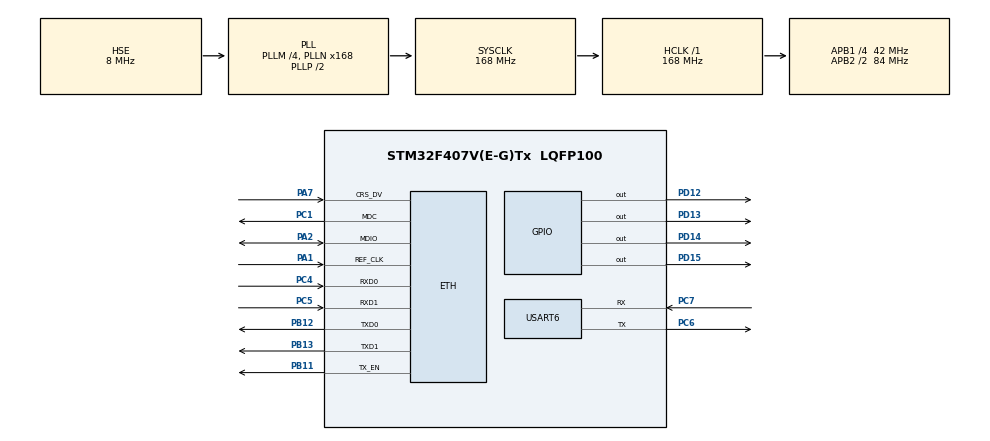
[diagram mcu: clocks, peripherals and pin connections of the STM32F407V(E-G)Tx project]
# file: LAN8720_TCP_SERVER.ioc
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ETH.MACAddr=00\:13\:37\:01\:23\:45
ETH.MediaInterface=ETH_MEDIA_INTERFACE_RMII
ETH.PhyAddress=0
LWIP.GATEWAY_ADDRESS=192.168.001.001
LWIP.IP_ADDRESS=192.168.001.193
LWIP.LWIP_DHCP=0
LWIP.MEMP_NUM_TCP_SEG=24
LWIP.NETMASK_ADDRESS=255.255.255.000
LWIP.TCP_MSS=460
LWIP.TCP_SND_BUF=1840
LWIP.TCP_WND=2048
LWIP.Version=v2.0.0_Cube
Mcu.Family=STM32F4
Mcu.Name=STM32F407V(E-G)Tx
Mcu.Package=LQFP100
NVIC.PriorityGroup=NVIC_PRIORITYGROUP_4
NVIC.TIM2_IRQn=true\:0\:0\:false\:false\:true\:true
NVIC.USART6_IRQn=true\:0\:0\:false\:false\:true\:true
PA1.Mode=RMII
PA1.Signal=ETH_REF_CLK
PA13.Mode=Serial_Wire
PA13.Signal=SYS_JTMS-SWDIO
PA14.Mode=Serial_Wire
PA14.Signal=SYS_JTCK-SWCLK
PA2.Mode=RMII
PA2.Signal=ETH_MDIO
PA7.Mode=RMII
PA7.Signal=ETH_CRS_DV
PB11.Mode=RMII
PB11.Signal=ETH_TX_EN
PB12.Mode=RMII
PB12.Signal=ETH_TXD0
PB13.Mode=RMII
PB13.Signal=ETH_TXD1
PC1.Mode=RMII
PC1.Signal=ETH_MDC
PC4.Mode=RMII
PC4.Signal=ETH_RXD0
PC5.Mode=RMII
PC5.Signal=ETH_RXD1
PC6.Mode=Asynchronous
PC6.Signal=USART6_TX
PC7.Mode=Asynchronous
PC7.Signal=USART6_RX
PD12.Signal=GPIO_Output
PD13.Signal=GPIO_Output
PD14.Signal=GPIO_Output
PD15.Signal=GPIO_Output
PH0-OSC_IN.Mode=HSE-External-Oscillator
PH0-OSC_IN.Signal=RCC_OSC_IN
PH1-OSC_OUT.Mode=HSE-External-Oscillator
PH1-OSC_OUT.Signal=RCC_OSC_OUT
ProjectManager.HeapSize=0x2000
ProjectManager.StackSize=0x4000
ProjectManager.TargetToolchain=SW4STM32
RCC.48MHZClocksFreq_Value=84000000
RCC.AHBFreq_Value=168000000
RCC.APB1CLKDivider=RCC_HCLK_DIV4
RCC.APB1Freq_Value=42000000
RCC.APB1TimFreq_Value=84000000
RCC.APB2CLKDivider=RCC_HCLK_DIV2
RCC.APB2Freq_Value=84000000
RCC.APB2TimFreq_Value=168000000
RCC.CortexFreq_Value=168000000
RCC.HCLKFreq_Value=168000000
RCC.HSE_VALUE=8000000
RCC.HSI_VALUE=16000000
RCC.LSE_VALUE=32768
RCC.PLLM=4
RCC.PLLN=168
RCC.PLLSourceVirtual=RCC_PLLSOURCE_HSE
RCC.SYSCLKFreq_VALUE=168000000
RCC.SYSCLKSource=RCC_SYSCLKSOURCE_PLLCLK
RCC.VCOOutputFreq_Value=336000000
TIM2.Period=1000
TIM2.Prescaler=41999
TIM2.TIM_MasterOutputTrigger=TIM_TRGO_UPDATE
USART6.VirtualMode=VM_ASYNC
VP_LWIP_VS_Enabled.Mode=Enabled
VP_TIM2_VS_ClockSourceINT.Mode=Internal
board=LAN8720_TCP_SERVER

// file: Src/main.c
/**
  ******************************************************************************
  * File Name          : main.c
  * Description        : Main program body
  ******************************************************************************
  * This notice applies to any and all portions of this file
  * that are not between comment pairs USER CODE BEGIN and
  * USER CODE END. Other portions of this file, whether
  * inserted by the user or by software development tools
  * are owned by their respective copyright owners.
  *
  * Copyright (c) 2017 STMicroelectronics International N.V.
  * All rights reserved.
  *
  * Redistribution and use in source and binary forms, with or without
  * modification, are permitted, provided that the following conditions are met:
  *
  * 1. Redistribution of source code must retain the above copyright notice,
  *    this list of conditions and the following disclaimer.
  * 2. Redistributions in binary form must reproduce the above copyright notice,
  *    this list of conditions and the following disclaimer in the documentation
  *    and/or other materials provided with the distribution.
  * 3. Neither the name of STMicroelectronics nor the names of other
  *    contributors to this software may be used to endorse or promote products
  *    derived from this software without specific written permission.
  * 4. This software, including modifications and/or derivative works of this
  *    software, must execute solely and exclusively on microcontroller or
  *    microprocessor devices manufactured by or for STMicroelectronics.
  * 5. Redistribution and use of this software other than as permitted under
  *    this license is void and will automatically terminate your rights under
  *    this license.
  *
  * THIS SOFTWARE IS PROVIDED BY STMICROELECTRONICS AND CONTRIBUTORS "AS IS"
  * AND ANY EXPRESS, IMPLIED OR STATUTORY WARRANTIES, INCLUDING, BUT NOT
  * LIMITED TO, THE IMPLIED WARRANTIES OF MERCHANTABILITY, FITNESS FOR A
  * PARTICULAR PURPOSE AND NON-INFRINGEMENT OF THIRD PARTY INTELLECTUAL PROPERTY
  * RIGHTS ARE DISCLAIMED TO THE FULLEST EXTENT PERMITTED BY LAW. IN NO EVENT
  * SHALL STMICROELECTRONICS OR CONTRIBUTORS BE LIABLE FOR ANY DIRECT, INDIRECT,
  * INCIDENTAL, SPECIAL, EXEMPLARY, OR CONSEQUENTIAL DAMAGES (INCLUDING, BUT NOT
  * LIMITED TO, PROCUREMENT OF SUBSTITUTE GOODS OR SERVICES; LOSS OF USE, DATA,
  * OR PROFITS; OR BUSINESS INTERRUPTION) HOWEVER CAUSED AND ON ANY THEORY OF
  * LIABILITY, WHETHER IN CONTRACT, STRICT LIABILITY, OR TORT (INCLUDING
  * NEGLIGENCE OR OTHERWISE) ARISING IN ANY WAY OUT OF THE USE OF THIS SOFTWARE,
  * EVEN IF ADVISED OF THE POSSIBILITY OF SUCH DAMAGE.
  *
  ******************************************************************************
  */
#include "main.h"
#include "stm32f4xx_hal.h"
#include "lwip.h"

/* USER CODE BEGIN Includes */
#include "net.h"
/* USER CODE END Includes */

TIM_HandleTypeDef htim2;

UART_HandleTypeDef huart6;

/* USER CODE BEGIN PV */
/* Private variables ---------------------------------------------------------*/
extern struct netif gnetif;
extern char str[30];
/* USER CODE END PV */

void SystemClock_Config(void);
static void MX_GPIO_Init(void);
static void MX_USART6_UART_Init(void);
static void MX_TIM2_Init(void);

/* USER CODE BEGIN PFP */
/* Private function prototypes -----------------------------------------------*/

/* USER CODE END PFP */

int main(void)
{

  /* MCU Configuration----------------------------------------------------------*/

  /* Reset of all peripherals, Initializes the Flash interface and the Systick. */
  HAL_Init();

  /* Configure the system clock */
  SystemClock_Config();

  /* Initialize all configured peripherals */
  MX_GPIO_Init();
  MX_USART6_UART_Init();
  MX_TIM2_Init();
  MX_LWIP_Init();

  /* USER CODE BEGIN 2 */
  HAL_TIM_Base_Start_IT(&htim2);
  net_ini();
  tcp_server_init();
  HAL_UART_Receive_IT(&huart6,(uint8_t*)str,1);
  /* USER CODE END 2 */

  /* Infinite loop */
  while (1)
  {

  /* USER CODE BEGIN 3 */
  ethernetif_input(&gnetif);
  sys_check_timeouts();
  }
  /* USER CODE END 3 */

}

/** System Clock Configuration
*/
void SystemClock_Config(void)
{

  RCC_OscInitTypeDef RCC_OscInitStruct;
  RCC_ClkInitTypeDef RCC_ClkInitStruct;

    /**Configure the main internal regulator output voltage
    */
  __HAL_RCC_PWR_CLK_ENABLE();

  __HAL_PWR_VOLTAGESCALING_CONFIG(PWR_REGULATOR_VOLTAGE_SCALE1);

    /**Initializes the CPU, AHB and APB busses clocks
    */
  RCC_OscInitStruct.OscillatorType = RCC_OSCILLATORTYPE_HSE;
  RCC_OscInitStruct.HSEState = RCC_HSE_ON;
  RCC_OscInitStruct.PLL.PLLState = RCC_PLL_ON;
  RCC_OscInitStruct.PLL.PLLSource = RCC_PLLSOURCE_HSE;
  RCC_OscInitStruct.PLL.PLLM = 4;
  RCC_OscInitStruct.PLL.PLLN = 168;
  RCC_OscInitStruct.PLL.PLLP = RCC_PLLP_DIV2;
  RCC_OscInitStruct.PLL.PLLQ = 4;
  if (HAL_RCC_OscConfig(&RCC_OscInitStruct) != HAL_OK)
  {
    _Error_Handler(__FILE__, __LINE__);
  }

    /**Initializes the CPU, AHB and APB busses clocks
    */
  RCC_ClkInitStruct.ClockType = RCC_CLOCKTYPE_HCLK|RCC_CLOCKTYPE_SYSCLK
                              |RCC_CLOCKTYPE_PCLK1|RCC_CLOCKTYPE_PCLK2;
  RCC_ClkInitStruct.SYSCLKSource = RCC_SYSCLKSOURCE_PLLCLK;
  RCC_ClkInitStruct.AHBCLKDivider = RCC_SYSCLK_DIV1;
  RCC_ClkInitStruct.APB1CLKDivider = RCC_HCLK_DIV4;
  RCC_ClkInitStruct.APB2CLKDivider = RCC_HCLK_DIV2;

  if (HAL_RCC_ClockConfig(&RCC_ClkInitStruct, FLASH_LATENCY_5) != HAL_OK)
  {
    _Error_Handler(__FILE__, __LINE__);
  }

    /**Configure the Systick interrupt time
    */
  HAL_SYSTICK_Config(HAL_RCC_GetHCLKFreq()/1000);

    /**Configure the Systick
    */
  HAL_SYSTICK_CLKSourceConfig(SYSTICK_CLKSOURCE_HCLK);

  /* SysTick_IRQn interrupt configuration */
  HAL_NVIC_SetPriority(SysTick_IRQn, 0, 0);
}

/* TIM2 init function */
static void MX_TIM2_Init(void)
{

  TIM_ClockConfigTypeDef sClockSourceConfig;
  TIM_MasterConfigTypeDef sMasterConfig;

  htim2.Instance = TIM2;
  htim2.Init.Prescaler = 41999;
  htim2.Init.CounterMode = TIM_COUNTERMODE_UP;
  htim2.Init.Period = 1000;
  htim2.Init.ClockDivision = TIM_CLOCKDIVISION_DIV1;
  if (HAL_TIM_Base_Init(&htim2) != HAL_OK)
  {
    _Error_Handler(__FILE__, __LINE__);
  }

  sClockSourceConfig.ClockSource = TIM_CLOCKSOURCE_INTERNAL;
  if (HAL_TIM_ConfigClockSource(&htim2, &sClockSourceConfig) != HAL_OK)
  {
    _Error_Handler(__FILE__, __LINE__);
  }

  sMasterConfig.MasterOutputTrigger = TIM_TRGO_UPDATE;
  sMasterConfig.MasterSlaveMode = TIM_MASTERSLAVEMODE_DISABLE;
  if (HAL_TIMEx_MasterConfigSynchronization(&htim2, &sMasterConfig) != HAL_OK)
  {
    _Error_Handler(__FILE__, __LINE__);
  }

}

/* USART6 init function */
static void MX_USART6_UART_Init(void)
{

  huart6.Instance = USART6;
  huart6.Init.BaudRate = 115200;
  huart6.Init.WordLength = UART_WORDLENGTH_8B;
  huart6.Init.StopBits = UART_STOPBITS_1;
  huart6.Init.Parity = UART_PARITY_NONE;
  huart6.Init.Mode = UART_MODE_TX_RX;
  huart6.Init.HwFlowCtl = UART_HWCONTROL_NONE;
  huart6.Init.OverSampling = UART_OVERSAMPLING_16;
  if (HAL_UART_Init(&huart6) != HAL_OK)
  {
    _Error_Handler(__FILE__, __LINE__);
  }

}

/** Configure pins as
        * Analog
        * Input
        * Output
        * EVENT_OUT
        * EXTI
*/
static void MX_GPIO_Init(void)
{

  GPIO_InitTypeDef GPIO_InitStruct;

  /* GPIO Ports Clock Enable */
  __HAL_RCC_GPIOH_CLK_ENABLE();
  __HAL_RCC_GPIOC_CLK_ENABLE();
  __HAL_RCC_GPIOA_CLK_ENABLE();
  __HAL_RCC_GPIOB_CLK_ENABLE();
  __HAL_RCC_GPIOD_CLK_ENABLE();

  /*Configure GPIO pin Output Level */
  HAL_GPIO_WritePin(GPIOD, GPIO_PIN_12|GPIO_PIN_13|GPIO_PIN_14|GPIO_PIN_15, GPIO_PIN_RESET);

  /*Configure GPIO pins : PD12 PD13 PD14 PD15 */
  GPIO_InitStruct.Pin = GPIO_PIN_12|GPIO_PIN_13|GPIO_PIN_14|GPIO_PIN_15;
  GPIO_InitStruct.Mode = GPIO_MODE_OUTPUT_PP;
  GPIO_InitStruct.Pull = GPIO_NOPULL;
  GPIO_InitStruct.Speed = GPIO_SPEED_FREQ_LOW;
  HAL_GPIO_Init(GPIOD, &GPIO_InitStruct);

}

/* USER CODE BEGIN 4 */
//-----------------------------------------------
void HAL_UART_RxCpltCallback(UART_HandleTypeDef *huart)
{
  if(huart==&huart6)
  {
    UART6_RxCpltCallback();
  }
}
//-----------------------------------------------
/* USER CODE END 4 */

void _Error_Handler(char * file, int line)
{
  while(1)
  {
  }
}

/************************ (C) COPYRIGHT STMicroelectronics *****END OF FILE****/
